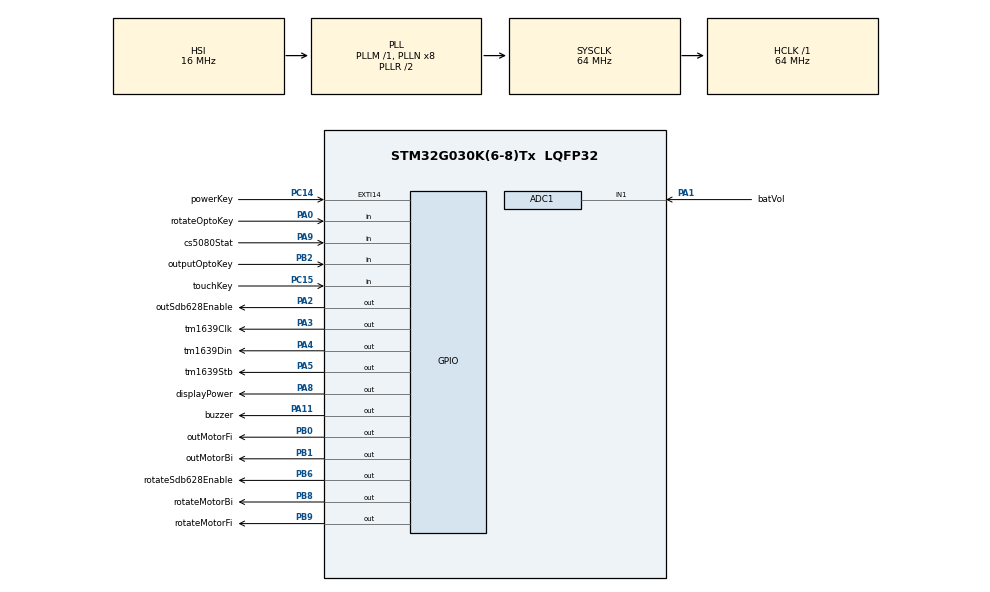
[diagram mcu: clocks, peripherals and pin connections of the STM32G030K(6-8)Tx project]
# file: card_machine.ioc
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ADC1.Channel-3\#ChannelRegularConversion=ADC_CHANNEL_1
ADC1.ClockPrescaler=ADC_CLOCK_SYNC_PCLK_DIV4
ADC1.ContinuousConvMode=ENABLE
ADC1.DMAContinuousRequests=ENABLE
ADC1.NbrOfConversion=1
ADC1.NbrOfConversionFlag=1
ADC1.Rank-3\#ChannelRegularConversion=1
ADC1.Resolution=ADC_RESOLUTION_10B
ADC1.SamplingTime-3\#ChannelRegularConversion=ADC_SAMPLINGTIME_COMMON_1
ADC1.SamplingTimeCommon1=ADC_SAMPLETIME_79CYCLES_5
ADC1.SamplingTimeCommon2=ADC_SAMPLETIME_79CYCLES_5
ADC1.SelectedChannel=ADC_CHANNEL_1
ADC1.Sequencer=FULLY_CONFIGURABLE
ADC1.master=1
Dma.ADC1.0.Direction=DMA_PERIPH_TO_MEMORY
Dma.ADC1.0.EventEnable=DISABLE
Dma.ADC1.0.Instance=DMA1_Channel1
Dma.ADC1.0.MemDataAlignment=DMA_MDATAALIGN_HALFWORD
Dma.ADC1.0.MemInc=DMA_MINC_ENABLE
Dma.ADC1.0.Mode=DMA_CIRCULAR
Dma.ADC1.0.PeriphDataAlignment=DMA_PDATAALIGN_HALFWORD
Dma.ADC1.0.PeriphInc=DMA_PINC_DISABLE
Dma.ADC1.0.Polarity=HAL_DMAMUX_REQ_GEN_RISING
Dma.ADC1.0.Priority=DMA_PRIORITY_LOW
Dma.ADC1.0.RequestNumber=1
Dma.ADC1.0.SignalID=NONE
Dma.ADC1.0.SyncEnable=DISABLE
Dma.ADC1.0.SyncPolarity=HAL_DMAMUX_SYNC_NO_EVENT
Dma.ADC1.0.SyncRequestNumber=1
Dma.ADC1.0.SyncSignalID=NONE
Dma.Request0=ADC1
FREERTOS.Tasks01=startTask,0,128,StartDefaultTask,As weak,NULL,Dynamic,NULL,NULL
FREERTOS.configUSE_TIMERS=1
Mcu.Family=STM32G0
Mcu.Name=STM32G030K(6-8)Tx
Mcu.Package=LQFP32
NVIC.DMA1_Channel1_IRQn=true\:3\:0\:false\:false\:true\:true\:false\:true\:true
NVIC.EXTI4_15_IRQn=true\:3\:0\:false\:false\:true\:true\:true\:true\:true
NVIC.TIM17_IRQn=true\:3\:0\:false\:false\:true\:false\:false\:true\:true
NVIC.TimeBase=TIM17_IRQn
NVIC.TimeBaseIP=TIM17
PA0.GPIO_Label=rotateOptoKey
PA0.GPIO_PuPd=GPIO_PULLUP
PA0.Signal=GPIO_Input
PA1.GPIO_Label=batVol
PA1.Mode=IN1
PA1.Signal=ADC1_IN1
PA11\ [PA9].GPIO_Label=buzzer
PA11\ [PA9].Signal=GPIO_Output
PA13.Mode=Serial_Wire
PA13.Signal=SYS_SWDIO
PA14-BOOT0.Mode=Serial_Wire
PA14-BOOT0.Signal=SYS_SWCLK
PA2.GPIO_Label=outSdb628Enable
PA2.Signal=GPIO_Output
PA3.GPIO_Label=tm1639Clk
PA3.GPIO_PuPd=GPIO_PULLUP
PA3.GPIO_Speed=GPIO_SPEED_FREQ_HIGH
PA3.Signal=GPIO_Output
PA4.GPIO_Label=tm1639Din
PA4.GPIO_PuPd=GPIO_PULLUP
PA4.GPIO_Speed=GPIO_SPEED_FREQ_HIGH
PA4.Signal=GPIO_Output
PA5.GPIO_Label=tm1639Stb
PA5.GPIO_PuPd=GPIO_PULLUP
PA5.GPIO_Speed=GPIO_SPEED_FREQ_HIGH
PA5.Signal=GPIO_Output
PA8.GPIO_Label=displayPower
PA8.PinState=GPIO_PIN_SET
PA8.Signal=GPIO_Output
PA9.GPIO_Label=cs5080Stat
PA9.Signal=GPIO_Input
PB0.GPIO_Label=outMotorFi
PB0.Signal=GPIO_Output
PB1.GPIO_Label=outMotorBi
PB1.Signal=GPIO_Output
PB2.GPIO_Label=outputOptoKey
PB2.GPIO_PuPd=GPIO_PULLUP
PB2.Signal=GPIO_Input
PB6.GPIO_Label=rotateSdb628Enable
PB6.Signal=GPIO_Output
PB8.GPIO_Label=rotateMotorBi
PB8.Signal=GPIO_Output
PB9.GPIO_Label=rotateMotorFi
PB9.Signal=GPIO_Output
PC14-OSC32_IN\ (PC14).GPIO_Label=powerKey
PC14-OSC32_IN\ (PC14).GPIO_ModeDefaultEXTI=GPIO_MODE_IT_FALLING
PC14-OSC32_IN\ (PC14).GPIO_PuPd=GPIO_PULLUP
PC14-OSC32_IN\ (PC14).Signal=GPXTI14
PC15-OSC32_OUT\ (PC15).GPIO_Label=touchKey
PC15-OSC32_OUT\ (PC15).Signal=GPIO_Input
ProjectManager.HeapSize=0x200
ProjectManager.StackSize=0x400
ProjectManager.TargetToolchain=MDK-ARM V5.32
RCC.ADCFreq_Value=64000000
RCC.AHBFreq_Value=64000000
RCC.CortexFreq_Value=64000000
RCC.EXTERNAL_CLOCK_VALUE=12288000
RCC.HCLKFreq_Value=64000000
RCC.HSE_VALUE=8000000
RCC.HSI_VALUE=16000000
RCC.LSE_VALUE=32768
RCC.SYSCLKFreq_VALUE=64000000
RCC.SYSCLKSource=RCC_SYSCLKSOURCE_PLLCLK
RCC.VCOOutputFreq_Value=128000000
VP_FREERTOS_VS_CMSIS_V1.Mode=CMSIS_V1
VP_SYS_VS_tim17.Mode=TIM17
board=custom

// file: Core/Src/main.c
/* USER CODE BEGIN Header */
/**
 ******************************************************************************
 * @file           : main.c
 * @brief          : Main program body
 ******************************************************************************
 * @attention
 *
 * Copyright (c) 2024 STMicroelectronics.
 * All rights reserved.
 *
 * This software is licensed under terms that can be found in the LICENSE file
 * in the root directory of this software component.
 * If no LICENSE file comes with this software, it is provided AS-IS.
 *
 ******************************************************************************
 */
/* USER CODE END Header */
#include "main.h"
#include "cmsis_os.h"
#include "adc.h"
#include "dma.h"
#include "gpio.h"

/* USER CODE BEGIN PTD */
uint16_t key_value = 0;
/* USER CODE END PTD */

void SystemClock_Config(void);
void MX_FREERTOS_Init(void);

int main(void)
{

  /* MCU Configuration--------------------------------------------------------*/

  /* Reset of all peripherals, Initializes the Flash interface and the Systick. */
  HAL_Init();

  /* Configure the system clock */
  SystemClock_Config();

  /* Initialize all configured peripherals */
  MX_GPIO_Init();
  MX_DMA_Init();
  MX_ADC1_Init();

  /* Call init function for freertos objects (in cmsis_os2.c) */
  MX_FREERTOS_Init();

  /* Start scheduler */
  osKernelStart();

  /* We should never get here as control is now taken by the scheduler */

  /* Infinite loop */
    while (1)
    {

    }
}

void SystemClock_Config(void)
{
  RCC_OscInitTypeDef RCC_OscInitStruct = {0};
  RCC_ClkInitTypeDef RCC_ClkInitStruct = {0};

  /** Configure the main internal regulator output voltage
  */
  HAL_PWREx_ControlVoltageScaling(PWR_REGULATOR_VOLTAGE_SCALE1);

  /** Initializes the RCC Oscillators according to the specified parameters
  * in the RCC_OscInitTypeDef structure.
  */
  RCC_OscInitStruct.OscillatorType = RCC_OSCILLATORTYPE_HSI;
  RCC_OscInitStruct.HSIState = RCC_HSI_ON;
  RCC_OscInitStruct.HSIDiv = RCC_HSI_DIV1;
  RCC_OscInitStruct.HSICalibrationValue = RCC_HSICALIBRATION_DEFAULT;
  RCC_OscInitStruct.PLL.PLLState = RCC_PLL_ON;
  RCC_OscInitStruct.PLL.PLLSource = RCC_PLLSOURCE_HSI;
  RCC_OscInitStruct.PLL.PLLM = RCC_PLLM_DIV1;
  RCC_OscInitStruct.PLL.PLLN = 8;
  RCC_OscInitStruct.PLL.PLLP = RCC_PLLP_DIV2;
  RCC_OscInitStruct.PLL.PLLR = RCC_PLLR_DIV2;
  if (HAL_RCC_OscConfig(&RCC_OscInitStruct) != HAL_OK)
  {
    Error_Handler();
  }

  /** Initializes the CPU, AHB and APB buses clocks
  */
  RCC_ClkInitStruct.ClockType = RCC_CLOCKTYPE_HCLK|RCC_CLOCKTYPE_SYSCLK
                              |RCC_CLOCKTYPE_PCLK1;
  RCC_ClkInitStruct.SYSCLKSource = RCC_SYSCLKSOURCE_PLLCLK;
  RCC_ClkInitStruct.AHBCLKDivider = RCC_SYSCLK_DIV1;
  RCC_ClkInitStruct.APB1CLKDivider = RCC_HCLK_DIV1;

  if (HAL_RCC_ClockConfig(&RCC_ClkInitStruct, FLASH_LATENCY_2) != HAL_OK)
  {
    Error_Handler();
  }
}

void HAL_TIM_PeriodElapsedCallback(TIM_HandleTypeDef *htim)
{
  if (htim->Instance == TIM17) {
    HAL_IncTick();
  }
}

void Error_Handler(void)
{
    __disable_irq();
    while (1)
    {
    }
}

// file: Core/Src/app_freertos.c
/* USER CODE BEGIN Header */
/**
  ******************************************************************************
  * File Name          : app_freertos.c
  * Description        : Code for freertos applications
  ******************************************************************************
  * @attention
  *
  * Copyright (c) 2024 STMicroelectronics.
  * All rights reserved.
  *
  * This software is licensed under terms that can be found in the LICENSE file
  * in the root directory of this software component.
  * If no LICENSE file comes with this software, it is provided AS-IS.
  *
  ******************************************************************************
  */
/* USER CODE END Header */

#include "FreeRTOS.h"
#include "task.h"
#include "main.h"
#include "cmsis_os.h"

osThreadId startTaskHandle;

void StartDefaultTask(void const * argument);

void MX_FREERTOS_Init(void); /* (MISRA C 2004 rule 8.1) */

void MX_FREERTOS_Init(void) {

  /* Create the thread(s) */
  /* definition and creation of startTask */
  osThreadDef(startTask, StartDefaultTask, osPriorityNormal, 0, 128);
  startTaskHandle = osThreadCreate(osThread(startTask), NULL);

}

__weak void StartDefaultTask(void const * argument)
{
  for(;;)
  {
    osDelay(1);
  }
}
